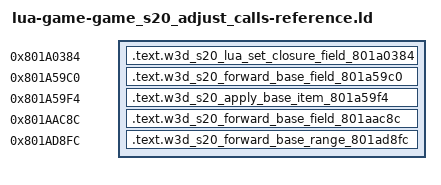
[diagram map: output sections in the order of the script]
/* Generated reference-only placements. All bodies are source-built. */
OUTPUT_FORMAT("elf32-powerpc")
OUTPUT_ARCH(powerpc)
ENTRY(w3d_s20_lua_set_closure_field_801a0384)
_SDA_BASE_ = 0x804b2540;
_SDA2_BASE_ = 0x804c2540;
fn_801a46bc = 0x801a46bc;
fn_801a572c = 0x801a572c;
fn_801a59c0 = 0x801a59c0;
fn_801ad790 = 0x801ad790;
fn_802cd8e0 = 0x802cd8e0;
fn_802cd99c = 0x802cd99c;
fn_802cdfd4 = 0x802cdfd4;
fn_802ce148 = 0x802ce148;
fn_802ce4d8 = 0x802ce4d8;
SECTIONS {
  .text.w3d_s20_lua_set_closure_field_801a0384 0x801a0384 : { *(.text.w3d_s20_lua_set_closure_field_801a0384) }
  .text.w3d_s20_forward_base_field_801a59c0 0x801a59c0 : { *(.text.w3d_s20_forward_base_field_801a59c0) }
  .text.w3d_s20_apply_base_item_801a59f4 0x801a59f4 : { *(.text.w3d_s20_apply_base_item_801a59f4) }
  .text.w3d_s20_forward_base_field_801aac8c 0x801aac8c : { *(.text.w3d_s20_forward_base_field_801aac8c) }
  .text.w3d_s20_forward_base_range_801ad8fc 0x801ad8fc : { *(.text.w3d_s20_forward_base_range_801ad8fc) }
  /DISCARD/ : { *(.text*) *(.rodata*) *(.data*) *(.bss*) *(.sdata*) *(.sbss*) *(.comment) }
}
